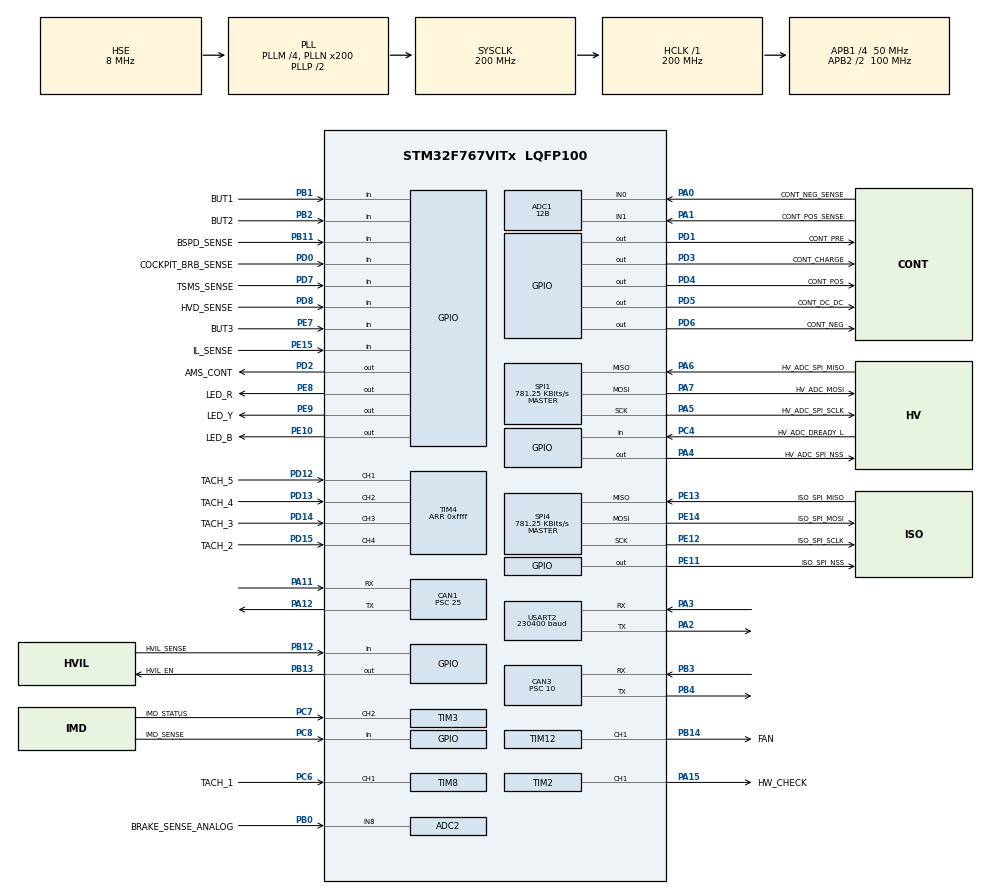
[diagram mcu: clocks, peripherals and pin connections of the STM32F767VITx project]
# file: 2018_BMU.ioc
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ADC1.Channel-0\#ChannelRegularConversion=ADC_CHANNEL_0
ADC1.ClockPrescaler=ADC_CLOCK_SYNC_PCLK_DIV4
ADC1.ContinuousConvMode=DISABLE
ADC1.DMAContinuousRequests=DISABLE
ADC1.DataAlign=ADC_DATAALIGN_RIGHT
ADC1.DiscontinuousConvMode=DISABLE
ADC1.EOCSelection=ADC_EOC_SINGLE_CONV
ADC1.EnableAnalogWatchDog=false
ADC1.ExternalTrigConv=ADC_EXTERNALTRIGCONV_T5_TRGO
ADC1.ExternalTrigConvEdge=ADC_EXTERNALTRIGCONVEDGE_RISING
ADC1.InjNumberOfConversion=0
ADC1.NbrOfConversion=1
ADC1.NbrOfConversionFlag=1
ADC1.Rank-0\#ChannelRegularConversion=1
ADC1.Resolution=ADC_RESOLUTION_12B
ADC1.SamplingTime-0\#ChannelRegularConversion=ADC_SAMPLETIME_3CYCLES
ADC1.ScanConvMode=ADC_SCAN_DISABLE
ADC1.master=1
ADC2.Channel-38\#ChannelRegularConversion=ADC_CHANNEL_8
ADC2.ClockPrescaler=ADC_CLOCK_SYNC_PCLK_DIV4
ADC2.ContinuousConvMode=DISABLE
ADC2.DMAContinuousRequests=ENABLE
ADC2.DataAlign=ADC_DATAALIGN_RIGHT
ADC2.DiscontinuousConvMode=DISABLE
ADC2.EOCSelection=ADC_EOC_SEQ_CONV
ADC2.EnableAnalogWatchDog=false
ADC2.ExternalTrigConv=ADC_EXTERNALTRIGCONV_T6_TRGO
ADC2.ExternalTrigConvEdge=ADC_EXTERNALTRIGCONVEDGE_RISING
ADC2.InjNumberOfConversion=0
ADC2.NbrOfConversion=1
ADC2.NbrOfConversionFlag=1
ADC2.Rank-38\#ChannelRegularConversion=1
ADC2.Resolution=ADC_RESOLUTION_12B
ADC2.SamplingTime-38\#ChannelRegularConversion=ADC_SAMPLETIME_28CYCLES
ADC2.ScanConvMode=ADC_SCAN_ENABLE
CAN1.BS1=CAN_BS1_6TQ
CAN1.CalculateBaudRate=250000
CAN1.CalculateTimeBit=4000
CAN1.CalculateTimeQuantum=500.0
CAN1.Prescaler=25
CAN3.ABOM=ENABLE
CAN3.AWUM=ENABLE
CAN3.BS1=CAN_BS1_8TQ
CAN3.CalculateBaudRate=500000
CAN3.CalculateTimeBit=2000
CAN3.CalculateTimeQuantum=200.0
CAN3.NART=ENABLE
CAN3.Prescaler=10
Dma.ADC2.1.Direction=DMA_PERIPH_TO_MEMORY
Dma.ADC2.1.FIFOMode=DMA_FIFOMODE_DISABLE
Dma.ADC2.1.Instance=DMA2_Stream2
Dma.ADC2.1.MemDataAlignment=DMA_MDATAALIGN_WORD
Dma.ADC2.1.MemInc=DMA_MINC_ENABLE
Dma.ADC2.1.Mode=DMA_CIRCULAR
Dma.ADC2.1.PeriphDataAlignment=DMA_PDATAALIGN_WORD
Dma.ADC2.1.PeriphInc=DMA_PINC_DISABLE
Dma.ADC2.1.Priority=DMA_PRIORITY_LOW
Dma.Request0=USART2_RX
Dma.Request1=ADC2
Dma.USART2_RX.0.Direction=DMA_PERIPH_TO_MEMORY
Dma.USART2_RX.0.FIFOMode=DMA_FIFOMODE_DISABLE
Dma.USART2_RX.0.Instance=DMA1_Stream5
Dma.USART2_RX.0.MemDataAlignment=DMA_MDATAALIGN_BYTE
Dma.USART2_RX.0.MemInc=DMA_MINC_ENABLE
Dma.USART2_RX.0.Mode=DMA_CIRCULAR
Dma.USART2_RX.0.PeriphDataAlignment=DMA_PDATAALIGN_BYTE
Dma.USART2_RX.0.PeriphInc=DMA_PINC_DISABLE
Dma.USART2_RX.0.Priority=DMA_PRIORITY_LOW
FREERTOS.INCLUDE_vTaskDelayUntil=1
FREERTOS.Tasks01=mainTask,0,1000,mainTaskFunction,As weak,NULL,Dynamic,NULL,NULL;printTaskName,-2,1000,printTask,As external,NULL,Dynamic,NULL,NULL;cliTaskName,-2,1000,cliTask,As external,NULL,Dynamic,NULL,NULL;controlTaskName,2,1000,controlTask,As external,NULL,Dynamic,NULL,NULL;PCDC,1,1000,pcdcTask,As external,NULL,Dynamic,NULL,NULL;BatteryTask,3,1000,batteryTask,As external,NULL,Dynamic,NULL,NULL;sensorTaskName,0,1000,sensorTask,As external,NULL,Dynamic,NULL,NULL;watchdogTaskNam,3,1000,watchdogTask,As external,NULL,Dynamic,NULL,NULL;HVMeasure,3,500,HVMeasureTask,As external,NULL,Dynamic,NULL,NULL;IMD,2,500,imdTask,As external,NULL,Dynamic,NULL,NULL;FaultMonitor,2,1000,faultMonitorTask,As external,NULL,Dynamic,NULL,NULL;canSendCells,0,1000,canSendCellTask,As external,NULL,Dynamic,NULL,NULL;canSendTask,3,1000,canTask,As external,NULL,Dynamic,NULL,NULL;fan,1,1000,fanTask,As external,NULL,Dynamic,NULL,NULL;stateOfCharge,0,500,socTask,Default,NULL,Dynamic,NULL,NULL
FREERTOS.configCHECK_FOR_STACK_OVERFLOW=2
FREERTOS.configGENERATE_RUN_TIME_STATS=1
FREERTOS.configTIMER_QUEUE_LENGTH=4
FREERTOS.configTIMER_TASK_PRIORITY=6
FREERTOS.configTIMER_TASK_STACK_DEPTH=1000
FREERTOS.configTOTAL_HEAP_SIZE=262144
FREERTOS.configUSE_COUNTING_SEMAPHORES=1
FREERTOS.configUSE_STATS_FORMATTING_FUNCTIONS=1
FREERTOS.configUSE_TIMERS=1
FREERTOS.configUSE_TRACE_FACILITY=1
IWDG.Reload=160
Mcu.Family=STM32F7
Mcu.Name=STM32F767VITx
Mcu.Package=LQFP100
NVIC.ADC_IRQn=true\:5\:0\:false\:false\:true\:true\:true\:true\:true
NVIC.CAN1_RX0_IRQn=true\:5\:0\:false\:false\:true\:true\:true\:true\:true
NVIC.CAN1_RX1_IRQn=true\:5\:0\:false\:false\:true\:true\:true\:true\:true
NVIC.CAN1_SCE_IRQn=true\:5\:0\:false\:false\:true\:true\:true\:true\:true
NVIC.CAN1_TX_IRQn=true\:5\:0\:false\:false\:true\:true\:true\:true\:true
NVIC.CAN3_RX0_IRQn=true\:5\:0\:false\:false\:true\:true\:true\:true\:true
NVIC.CAN3_RX1_IRQn=true\:5\:0\:false\:false\:true\:true\:true\:true\:true
NVIC.CAN3_SCE_IRQn=true\:5\:0\:false\:false\:true\:true\:true\:true\:true
NVIC.CAN3_TX_IRQn=true\:5\:0\:false\:false\:true\:true\:true\:true\:true
NVIC.DMA1_Stream5_IRQn=true\:5\:0\:false\:false\:true\:true\:false\:true\:true
NVIC.DMA2_Stream2_IRQn=true\:5\:0\:false\:false\:true\:true\:false\:true\:true
NVIC.PriorityGroup=NVIC_PRIORITYGROUP_4
NVIC.TIM3_IRQn=true\:5\:0\:false\:false\:true\:true\:true\:true\:true
NVIC.USART2_IRQn=true\:5\:0\:false\:false\:true\:true\:true\:true\:true
PA0/WKUP.GPIO_Label=CONT_NEG_SENSE
PA0/WKUP.Signal=ADCx_IN0
PA1.GPIO_Label=CONT_POS_SENSE
PA1.Signal=ADCx_IN1
PA11.Mode=CAN_Activate
PA11.Signal=CAN1_RX
PA12.Mode=CAN_Activate
PA12.Signal=CAN1_TX
PA13.Mode=Serial_Wire
PA13.Signal=SYS_JTMS-SWDIO
PA14.Mode=Serial_Wire
PA14.Signal=SYS_JTCK-SWCLK
PA15.GPIO_Label=HW_CHECK
PA15.GPIO_Speed=GPIO_SPEED_FREQ_LOW
PA15.Signal=S_TIM2_CH1_ETR
PA2.Mode=Asynchronous
PA2.Signal=USART2_TX
PA3.Mode=Asynchronous
PA3.Signal=USART2_RX
PA4.GPIO_Label=HV_ADC_SPI_NSS
PA4.GPIO_Speed=GPIO_SPEED_FREQ_VERY_HIGH
PA4.PinState=GPIO_PIN_SET
PA4.Signal=GPIO_Output
PA5.GPIO_Label=HV_ADC_SPI_SCLK
PA5.Mode=Full_Duplex_Master
PA5.Signal=SPI1_SCK
PA6.GPIO_Label=HV_ADC_SPI_MISO
PA6.Mode=Full_Duplex_Master
PA6.Signal=SPI1_MISO
PA7.GPIO_Label=HV_ADC_MOSI
PA7.Mode=Full_Duplex_Master
PA7.Signal=SPI1_MOSI
PB0.GPIO_Label=BRAKE_SENSE_ANALOG
PB0.Signal=ADCx_IN8
PB1.GPIO_Label=BUT1
PB1.Signal=GPIO_Input
PB11.GPIO_Label=BSPD_SENSE
PB11.Signal=GPIO_Input
PB12.GPIO_Label=HVIL_SENSE
PB12.GPIO_PuPd=GPIO_PULLDOWN
PB12.Signal=GPIO_Input
PB13.GPIO_Label=HVIL_EN
PB13.Signal=GPIO_Output
PB14.GPIO_Label=FAN
PB14.Signal=S_TIM12_CH1
PB2.GPIO_Label=BUT2
PB2.Signal=GPIO_Input
PB3.Mode=CAN_Activate
PB3.Signal=CAN3_RX
PB4.Mode=CAN_Activate
PB4.Signal=CAN3_TX
PC4.GPIO_Label=HV_ADC_DREADY_L
PC4.Signal=GPIO_Input
PC6.GPIO_Label=TACH_1
PC6.Signal=S_TIM8_CH1
PC7.GPIO_Label=IMD_STATUS
PC7.Signal=S_TIM3_CH2
PC8.GPIO_Label=IMD_SENSE
PC8.GPIO_PuPd=GPIO_PULLDOWN
PC8.Signal=GPIO_Input
PD0.GPIO_Label=COCKPIT_BRB_SENSE
PD0.GPIO_PuPd=GPIO_PULLDOWN
PD0.Signal=GPIO_Input
PD1.GPIO_Label=CONT_PRE
PD1.Signal=GPIO_Output
PD12.GPIO_Label=TACH_5
PD12.Signal=S_TIM4_CH1
PD13.GPIO_Label=TACH_4
PD13.Signal=S_TIM4_CH2
PD14.GPIO_Label=TACH_3
PD14.Signal=S_TIM4_CH3
PD15.GPIO_Label=TACH_2
PD15.Signal=S_TIM4_CH4
PD2.GPIO_Label=AMS_CONT
PD2.Signal=GPIO_Output
PD3.GPIO_Label=CONT_CHARGE
PD3.Signal=GPIO_Output
PD4.GPIO_Label=CONT_POS
PD4.Signal=GPIO_Output
PD5.GPIO_Label=CONT_DC_DC
PD5.Signal=GPIO_Output
PD6.GPIO_Label=CONT_NEG
PD6.Signal=GPIO_Output
PD7.GPIO_Label=TSMS_SENSE
PD7.GPIO_PuPd=GPIO_PULLDOWN
PD7.Signal=GPIO_Input
PD8.GPIO_Label=HVD_SENSE
PD8.GPIO_PuPd=GPIO_PULLDOWN
PD8.Signal=GPIO_Input
PE10.GPIO_Label=LED_B
PE10.Signal=GPIO_Output
PE11.GPIO_Label=ISO_SPI_NSS
PE11.GPIO_Speed=GPIO_SPEED_FREQ_VERY_HIGH
PE11.PinState=GPIO_PIN_SET
PE11.Signal=GPIO_Output
PE12.GPIO_Label=ISO_SPI_SCLK
PE12.Mode=Full_Duplex_Master
PE12.Signal=SPI4_SCK
PE13.GPIO_Label=ISO_SPI_MISO
PE13.Mode=Full_Duplex_Master
PE13.Signal=SPI4_MISO
PE14.GPIO_Label=ISO_SPI_MOSI
PE14.Mode=Full_Duplex_Master
PE14.Signal=SPI4_MOSI
PE15.GPIO_Label=IL_SENSE
PE15.GPIO_PuPd=GPIO_PULLDOWN
PE15.Signal=GPIO_Input
PE7.GPIO_Label=BUT3
PE7.Signal=GPIO_Input
PE8.GPIO_Label=LED_R
PE8.Signal=GPIO_Output
PE9.GPIO_Label=LED_Y
PE9.Signal=GPIO_Output
PH0/OSC_IN.Mode=HSE-External-Oscillator
PH0/OSC_IN.Signal=RCC_OSC_IN
PH1/OSC_OUT.Mode=HSE-External-Oscillator
PH1/OSC_OUT.Signal=RCC_OSC_OUT
ProjectManager.HeapSize=0x200
ProjectManager.StackSize=0x400
ProjectManager.TargetToolchain=Makefile
RCC.AHBFreq_Value=200000000
RCC.APB1CLKDivider=RCC_HCLK_DIV4
RCC.APB1Freq_Value=50000000
RCC.APB1TimFreq_Value=100000000
RCC.APB2CLKDivider=RCC_HCLK_DIV2
RCC.APB2Freq_Value=100000000
RCC.APB2TimFreq_Value=200000000
RCC.CortexFreq_Value=200000000
RCC.HCLKFreq_Value=200000000
RCC.HSE_VALUE=8000000
RCC.HSI_VALUE=16000000
RCC.LSE_VALUE=32768
RCC.PLLM=4
RCC.PLLN=200
RCC.PLLSourceVirtual=RCC_PLLSOURCE_HSE
RCC.SYSCLKFreq_VALUE=200000000
RCC.SYSCLKSource=RCC_SYSCLKSOURCE_PLLCLK
RCC.USBFreq_Value=200000000
RCC.VCOOutputFreq_Value=400000000
SH.ADCx_IN0.0=ADC1_IN0,IN0
SH.ADCx_IN1.0=ADC1_IN1,IN1
SH.ADCx_IN8.0=ADC2_IN8,IN8
SH.S_TIM12_CH1.0=TIM12_CH1,PWM Generation1 CH1
SH.S_TIM2_CH1_ETR.0=TIM2_CH1,PWM Generation1 CH1
SH.S_TIM3_CH2.0=TIM3_CH2,TriggerSource_TI2FP2
SH.S_TIM3_CH2.1=TIM3_CH2,Input_Capture2_from_TI2
SH.S_TIM3_CH2.2=TIM3_CH2,Input_Capture1_from_TI2
SH.S_TIM4_CH1.0=TIM4_CH1,Input_Capture1_from_TI1
SH.S_TIM4_CH2.0=TIM4_CH2,Input_Capture2_from_TI2
SH.S_TIM4_CH3.0=TIM4_CH3,Input_Capture3_from_TI3
SH.S_TIM4_CH4.0=TIM4_CH4,Input_Capture4_from_TI4
SH.S_TIM8_CH1.0=TIM8_CH1,Input_Capture1_from_TI1
SPI1.BaudRatePrescaler=SPI_BAUDRATEPRESCALER_128
SPI1.CLKPhase=SPI_PHASE_2EDGE
SPI1.CLKPolarity=SPI_POLARITY_HIGH
SPI1.CalculateBaudRate=781.25 KBits/s
SPI1.DataSize=SPI_DATASIZE_8BIT
SPI1.Direction=SPI_DIRECTION_2LINES
SPI1.Mode=SPI_MODE_MASTER
SPI1.VirtualType=VM_MASTER
SPI4.BaudRatePrescaler=SPI_BAUDRATEPRESCALER_128
SPI4.CLKPhase=SPI_PHASE_2EDGE
SPI4.CLKPolarity=SPI_POLARITY_HIGH
SPI4.CalculateBaudRate=781.25 KBits/s
SPI4.DataSize=SPI_DATASIZE_8BIT
SPI4.Direction=SPI_DIRECTION_2LINES
SPI4.Mode=SPI_MODE_MASTER
SPI4.VirtualType=VM_MASTER
TIM12.Channel-PWM\ Generation1\ CH1=TIM_CHANNEL_1
TIM12.Period=400
TIM12.Prescaler=9
TIM12.Pulse-PWM\ Generation1\ CH1=500
TIM2.AutoReloadPreload=TIM_AUTORELOAD_PRELOAD_DISABLE
TIM2.Channel-PWM\ Generation1\ CH1=TIM_CHANNEL_1
TIM2.Period=1000
TIM2.Prescaler=0
TIM2.Pulse-PWM\ Generation1\ CH1=500
TIM3.Channel-Input_Capture1_from_TI2=TIM_CHANNEL_1
TIM3.Channel-Input_Capture2_from_TI2=TIM_CHANNEL_2
TIM3.ICPolarity_CH1=TIM_INPUTCHANNELPOLARITY_FALLING
TIM3.Period=0xFFFF
TIM3.TIM_MasterOutputTrigger=TIM_TRGO_RESET
TIM4.Channel-Input_Capture1_from_TI1=TIM_CHANNEL_1
TIM4.Channel-Input_Capture2_from_TI2=TIM_CHANNEL_2
TIM4.Channel-Input_Capture3_from_TI3=TIM_CHANNEL_3
TIM4.Channel-Input_Capture4_from_TI4=TIM_CHANNEL_4
TIM4.Period=0xffff
TIM5.AutoReloadPreload=TIM_AUTORELOAD_PRELOAD_ENABLE
TIM5.CounterMode=TIM_COUNTERMODE_DOWN
TIM5.Period=1000
TIM5.Prescaler=16
TIM5.TIM_MasterOutputTrigger=TIM_TRGO_UPDATE
TIM6.AutoReloadPreload=TIM_AUTORELOAD_PRELOAD_ENABLE
TIM6.Period=10
TIM6.Prescaler=9999
TIM6.TIM_MasterOutputTrigger=TIM_TRGO_UPDATE
TIM8.Channel-Input_Capture1_from_TI1=TIM_CHANNEL_1
TIM9.Period=65535
TIM9.Prescaler=200
USART2.BaudRate=230400
USART2.VirtualMode-Asynchronous=VM_ASYNC
USART2.WordLength=WORDLENGTH_8B
VP_FREERTOS_VS_CMSIS_V1.Mode=CMSIS_V1
VP_IWDG_VS_IWDG.Mode=IWDG_Activate
VP_TIM2_VS_ClockSourceINT.Mode=Internal
VP_TIM3_VS_ClockSourceINT.Mode=Internal
VP_TIM3_VS_ControllerModeReset.Mode=Reset Mode
VP_TIM4_VS_ClockSourceINT.Mode=Internal
VP_TIM5_VS_ClockSourceINT.Mode=Internal
VP_TIM6_VS_ClockSourceINT.Mode=Enable_Timer
VP_TIM9_VS_ClockSourceINT.Mode=Internal
board=2018_bmu

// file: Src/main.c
/* USER CODE BEGIN Header */
/**
  ******************************************************************************
  * @file           : main.c
  * @brief          : Main program body
  ******************************************************************************
  * This notice applies to any and all portions of this file
  * that are not between comment pairs USER CODE BEGIN and
  * USER CODE END. Other portions of this file, whether
  * inserted by the user or by software development tools
  * are owned by their respective copyright owners.
  *
  * Copyright (c) 2018 STMicroelectronics International N.V.
  * All rights reserved.
  *
  * Redistribution and use in source and binary forms, with or without
  * modification, are permitted, provided that the following conditions are met:
  *
  * 1. Redistribution of source code must retain the above copyright notice,
  *    this list of conditions and the following disclaimer.
  * 2. Redistributions in binary form must reproduce the above copyright notice,
  *    this list of conditions and the following disclaimer in the documentation
  *    and/or other materials provided with the distribution.
  * 3. Neither the name of STMicroelectronics nor the names of other
  *    contributors to this software may be used to endorse or promote products
  *    derived from this software without specific written permission.
  * 4. This software, including modifications and/or derivative works of this
  *    software, must execute solely and exclusively on microcontroller or
  *    microprocessor devices manufactured by or for STMicroelectronics.
  * 5. Redistribution and use of this software other than as permitted under
  *    this license is void and will automatically terminate your rights under
  *    this license.
  *
  * THIS SOFTWARE IS PROVIDED BY STMICROELECTRONICS AND CONTRIBUTORS "AS IS"
  * AND ANY EXPRESS, IMPLIED OR STATUTORY WARRANTIES, INCLUDING, BUT NOT
  * LIMITED TO, THE IMPLIED WARRANTIES OF MERCHANTABILITY, FITNESS FOR A
  * PARTICULAR PURPOSE AND NON-INFRINGEMENT OF THIRD PARTY INTELLECTUAL PROPERTY
  * RIGHTS ARE DISCLAIMED TO THE FULLEST EXTENT PERMITTED BY LAW. IN NO EVENT
  * SHALL STMICROELECTRONICS OR CONTRIBUTORS BE LIABLE FOR ANY DIRECT, INDIRECT,
  * INCIDENTAL, SPECIAL, EXEMPLARY, OR CONSEQUENTIAL DAMAGES (INCLUDING, BUT NOT
  * LIMITED TO, PROCUREMENT OF SUBSTITUTE GOODS OR SERVICES; LOSS OF USE, DATA,
  * OR PROFITS; OR BUSINESS INTERRUPTION) HOWEVER CAUSED AND ON ANY THEORY OF
  * LIABILITY, WHETHER IN CONTRACT, STRICT LIABILITY, OR TORT (INCLUDING
  * NEGLIGENCE OR OTHERWISE) ARISING IN ANY WAY OUT OF THE USE OF THIS SOFTWARE,
  * EVEN IF ADVISED OF THE POSSIBILITY OF SUCH DAMAGE.
  *
  ******************************************************************************
  */
/* USER CODE END Header */
#include "main.h"
#include "cmsis_os.h"
#include "adc.h"
#include "can.h"
#include "dma.h"
#include "iwdg.h"
#include "spi.h"
#include "tim.h"
#include "usart.h"
#include "gpio.h"

/* USER CODE BEGIN Includes */
#include "watchdog.h"
#include "generalErrorHandler.h"
/* USER CODE END Includes */

void SystemClock_Config(void);
void MX_FREERTOS_Init(void);
/* USER CODE BEGIN PFP */
__weak void userInit() {}
/* USER CODE END PFP */

int main(void)
{
  /* USER CODE BEGIN 1 */
  checkForWDReset();
  /* USER CODE END 1 */

  /* MCU Configuration--------------------------------------------------------*/

  /* Reset of all peripherals, Initializes the Flash interface and the Systick. */
  HAL_Init();

  /* Configure the system clock */
  SystemClock_Config();

  /* Initialize all configured peripherals */
  MX_GPIO_Init();
  MX_DMA_Init();
  MX_ADC1_Init();
  MX_ADC2_Init();
  MX_CAN3_Init();
  MX_SPI1_Init();
  MX_SPI4_Init();
  MX_TIM3_Init();
  MX_TIM5_Init();
  MX_USART2_UART_Init();
  MX_TIM4_Init();
  MX_IWDG_Init();
  MX_TIM6_Init();
  MX_TIM9_Init();
  MX_CAN1_Init();
  MX_TIM8_Init();
  MX_TIM12_Init();
  MX_TIM2_Init();
  /* USER CODE BEGIN 2 */
  userInit();
  printWDResetState();
  handleWatchdogReset();
  /* USER CODE END 2 */

  /* Call init function for freertos objects (in freertos.c) */
  MX_FREERTOS_Init();
  /* Start scheduler */
  osKernelStart();

  /* We should never get here as control is now taken by the scheduler */
  /* Infinite loop */
  while (1)
  {

  }
}

void SystemClock_Config(void)
{
  RCC_OscInitTypeDef RCC_OscInitStruct = {0};
  RCC_ClkInitTypeDef RCC_ClkInitStruct = {0};
  RCC_PeriphCLKInitTypeDef PeriphClkInitStruct = {0};

  /** Configure the main internal regulator output voltage
  */
  __HAL_RCC_PWR_CLK_ENABLE();
  __HAL_PWR_VOLTAGESCALING_CONFIG(PWR_REGULATOR_VOLTAGE_SCALE1);
  /** Initializes the RCC Oscillators according to the specified parameters
  * in the RCC_OscInitTypeDef structure.
  */
  RCC_OscInitStruct.OscillatorType = RCC_OSCILLATORTYPE_LSI|RCC_OSCILLATORTYPE_HSE;
  RCC_OscInitStruct.HSEState = RCC_HSE_ON;
  RCC_OscInitStruct.LSIState = RCC_LSI_ON;
  RCC_OscInitStruct.PLL.PLLState = RCC_PLL_ON;
  RCC_OscInitStruct.PLL.PLLSource = RCC_PLLSOURCE_HSE;
  RCC_OscInitStruct.PLL.PLLM = 4;
  RCC_OscInitStruct.PLL.PLLN = 200;
  RCC_OscInitStruct.PLL.PLLP = RCC_PLLP_DIV2;
  RCC_OscInitStruct.PLL.PLLQ = 2;
  RCC_OscInitStruct.PLL.PLLR = 2;
  if (HAL_RCC_OscConfig(&RCC_OscInitStruct) != HAL_OK)
  {
    Error_Handler();
  }
  /** Activate the Over-Drive mode
  */
  if (HAL_PWREx_EnableOverDrive() != HAL_OK)
  {
    Error_Handler();
  }
  /** Initializes the CPU, AHB and APB buses clocks
  */
  RCC_ClkInitStruct.ClockType = RCC_CLOCKTYPE_HCLK|RCC_CLOCKTYPE_SYSCLK
                              |RCC_CLOCKTYPE_PCLK1|RCC_CLOCKTYPE_PCLK2;
  RCC_ClkInitStruct.SYSCLKSource = RCC_SYSCLKSOURCE_PLLCLK;
  RCC_ClkInitStruct.AHBCLKDivider = RCC_SYSCLK_DIV1;
  RCC_ClkInitStruct.APB1CLKDivider = RCC_HCLK_DIV4;
  RCC_ClkInitStruct.APB2CLKDivider = RCC_HCLK_DIV2;

  if (HAL_RCC_ClockConfig(&RCC_ClkInitStruct, FLASH_LATENCY_6) != HAL_OK)
  {
    Error_Handler();
  }
  PeriphClkInitStruct.PeriphClockSelection = RCC_PERIPHCLK_USART2;
  PeriphClkInitStruct.Usart2ClockSelection = RCC_USART2CLKSOURCE_PCLK1;
  if (HAL_RCCEx_PeriphCLKConfig(&PeriphClkInitStruct) != HAL_OK)
  {
    Error_Handler();
  }
}

void Error_Handler(void)
{
  __disable_irq();
  while (1)
  {
  }
}

/************************ (C) COPYRIGHT STMicroelectronics *****END OF FILE****/

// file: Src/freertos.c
/* USER CODE BEGIN Header */
/**
  ******************************************************************************
  * File Name          : freertos.c
  * Description        : Code for freertos applications
  ******************************************************************************
  * This notice applies to any and all portions of this file
  * that are not between comment pairs USER CODE BEGIN and
  * USER CODE END. Other portions of this file, whether
  * inserted by the user or by software development tools
  * are owned by their respective copyright owners.
  *
  * Copyright (c) 2018 STMicroelectronics International N.V.
  * All rights reserved.
  *
  * Redistribution and use in source and binary forms, with or without
  * modification, are permitted, provided that the following conditions are met:
  *
  * 1. Redistribution of source code must retain the above copyright notice,
  *    this list of conditions and the following disclaimer.
  * 2. Redistributions in binary form must reproduce the above copyright notice,
  *    this list of conditions and the following disclaimer in the documentation
  *    and/or other materials provided with the distribution.
  * 3. Neither the name of STMicroelectronics nor the names of other
  *    contributors to this software may be used to endorse or promote products
  *    derived from this software without specific written permission.
  * 4. This software, including modifications and/or derivative works of this
  *    software, must execute solely and exclusively on microcontroller or
  *    microprocessor devices manufactured by or for STMicroelectronics.
  * 5. Redistribution and use of this software other than as permitted under
  *    this license is void and will automatically terminate your rights under
  *    this license.
  *
  * THIS SOFTWARE IS PROVIDED BY STMICROELECTRONICS AND CONTRIBUTORS "AS IS"
  * AND ANY EXPRESS, IMPLIED OR STATUTORY WARRANTIES, INCLUDING, BUT NOT
  * LIMITED TO, THE IMPLIED WARRANTIES OF MERCHANTABILITY, FITNESS FOR A
  * PARTICULAR PURPOSE AND NON-INFRINGEMENT OF THIRD PARTY INTELLECTUAL PROPERTY
  * RIGHTS ARE DISCLAIMED TO THE FULLEST EXTENT PERMITTED BY LAW. IN NO EVENT
  * SHALL STMICROELECTRONICS OR CONTRIBUTORS BE LIABLE FOR ANY DIRECT, INDIRECT,
  * INCIDENTAL, SPECIAL, EXEMPLARY, OR CONSEQUENTIAL DAMAGES (INCLUDING, BUT NOT
  * LIMITED TO, PROCUREMENT OF SUBSTITUTE GOODS OR SERVICES; LOSS OF USE, DATA,
  * OR PROFITS; OR BUSINESS INTERRUPTION) HOWEVER CAUSED AND ON ANY THEORY OF
  * LIABILITY, WHETHER IN CONTRACT, STRICT LIABILITY, OR TORT (INCLUDING
  * NEGLIGENCE OR OTHERWISE) ARISING IN ANY WAY OUT OF THE USE OF THIS SOFTWARE,
  * EVEN IF ADVISED OF THE POSSIBILITY OF SUCH DAMAGE.
  *
  ******************************************************************************
  */
/* USER CODE END Header */

#include "FreeRTOS.h"
#include "task.h"
#include "main.h"
#include "cmsis_os.h"

osThreadId mainTaskHandle;
osThreadId printTaskNameHandle;
osThreadId cliTaskNameHandle;
osThreadId controlTaskNameHandle;
osThreadId PCDCHandle;
osThreadId BatteryTaskHandle;
osThreadId sensorTaskNameHandle;
osThreadId watchdogTaskNamHandle;
osThreadId HVMeasureHandle;
osThreadId IMDHandle;
osThreadId FaultMonitorHandle;
osThreadId canSendCellsHandle;
osThreadId canSendTaskHandle;
osThreadId fanHandle;
osThreadId stateOfChargeHandle;
osThreadId wirelessCANHandle;

void mainTaskFunction(void const * argument);
extern void printTask(void const * argument);
extern void cliTask(void const * argument);
extern void controlTask(void const * argument);
extern void pcdcTask(void const * argument);
extern void batteryTask(void const * argument);
extern void sensorTask(void const * argument);
extern void watchdogTask(void const * argument);
extern void HVMeasureTask(void const * argument);
extern void imdTask(void const * argument);
extern void faultMonitorTask(void const * argument);
extern void canSendCellTask(void const * argument);
extern void canTask(void const * argument);
extern void fanTask(void const * argument);
void socTask(void const * argument);
extern void wirelessCANTask(void const * argument);

void MX_FREERTOS_Init(void); /* (MISRA C 2004 rule 8.1) */

/* GetIdleTaskMemory prototype (linked to static allocation support) */
void vApplicationGetIdleTaskMemory( StaticTask_t **ppxIdleTaskTCBBuffer, StackType_t **ppxIdleTaskStackBuffer, uint32_t *pulIdleTaskStackSize );

/* GetTimerTaskMemory prototype (linked to static allocation support) */
void vApplicationGetTimerTaskMemory( StaticTask_t **ppxTimerTaskTCBBuffer, StackType_t **ppxTimerTaskStackBuffer, uint32_t *pulTimerTaskStackSize );

/* Hook prototypes */
void configureTimerForRunTimeStats(void);
unsigned long getRunTimeCounterValue(void);
void vApplicationStackOverflowHook(xTaskHandle xTask, signed char *pcTaskName);

/* USER CODE BEGIN 1 */
/* Functions needed when configGENERATE_RUN_TIME_STATS is on */
__weak void configureTimerForRunTimeStats(void)
{

}

__weak unsigned long getRunTimeCounterValue(void)
{
return 0;
}
/* USER CODE END 1 */

/* USER CODE BEGIN 4 */
__weak void vApplicationStackOverflowHook(xTaskHandle xTask, signed char *pcTaskName)
{
   /* Run time stack overflow checking is performed if
   configCHECK_FOR_STACK_OVERFLOW is defined to 1 or 2. This hook function is
   called if a stack overflow is detected. */
}
/* USER CODE END 4 */

/* USER CODE BEGIN GET_IDLE_TASK_MEMORY */
static StaticTask_t xIdleTaskTCBBuffer;
static StackType_t xIdleStack[configMINIMAL_STACK_SIZE];

void vApplicationGetIdleTaskMemory( StaticTask_t **ppxIdleTaskTCBBuffer, StackType_t **ppxIdleTaskStackBuffer, uint32_t *pulIdleTaskStackSize )
{
  *ppxIdleTaskTCBBuffer = &xIdleTaskTCBBuffer;
  *ppxIdleTaskStackBuffer = &xIdleStack[0];
  *pulIdleTaskStackSize = configMINIMAL_STACK_SIZE;
  /* place for user code */
}
/* USER CODE END GET_IDLE_TASK_MEMORY */

/* USER CODE BEGIN GET_TIMER_TASK_MEMORY */
static StaticTask_t xTimerTaskTCBBuffer;
static StackType_t xTimerStack[configTIMER_TASK_STACK_DEPTH];

void vApplicationGetTimerTaskMemory( StaticTask_t **ppxTimerTaskTCBBuffer, StackType_t **ppxTimerTaskStackBuffer, uint32_t *pulTimerTaskStackSize )
{
  *ppxTimerTaskTCBBuffer = &xTimerTaskTCBBuffer;
  *ppxTimerTaskStackBuffer = &xTimerStack[0];
  *pulTimerTaskStackSize = configTIMER_TASK_STACK_DEPTH;
  /* place for user code */
}
/* USER CODE END GET_TIMER_TASK_MEMORY */

void MX_FREERTOS_Init(void) {

  /* Create the thread(s) */
  /* definition and creation of mainTask */
  osThreadDef(mainTask, mainTaskFunction, osPriorityNormal, 0, 1000);
  mainTaskHandle = osThreadCreate(osThread(mainTask), NULL);

  /* definition and creation of printTaskName */
  osThreadDef(printTaskName, printTask, osPriorityLow, 0, 1000);
  printTaskNameHandle = osThreadCreate(osThread(printTaskName), NULL);

  /* definition and creation of cliTaskName */
  osThreadDef(cliTaskName, cliTask, osPriorityLow, 0, 1000);
  cliTaskNameHandle = osThreadCreate(osThread(cliTaskName), NULL);

  /* definition and creation of controlTaskName */
  osThreadDef(controlTaskName, controlTask, osPriorityHigh, 0, 1000);
  controlTaskNameHandle = osThreadCreate(osThread(controlTaskName), NULL);

  /* definition and creation of PCDC */
  osThreadDef(PCDC, pcdcTask, osPriorityAboveNormal, 0, 1000);
  PCDCHandle = osThreadCreate(osThread(PCDC), NULL);

  /* definition and creation of BatteryTask */
  osThreadDef(BatteryTask, batteryTask, osPriorityRealtime, 0, 1000);
  BatteryTaskHandle = osThreadCreate(osThread(BatteryTask), NULL);

  /* definition and creation of sensorTaskName */
  osThreadDef(sensorTaskName, sensorTask, osPriorityNormal, 0, 1000);
  sensorTaskNameHandle = osThreadCreate(osThread(sensorTaskName), NULL);

  /* definition and creation of watchdogTaskNam */
  osThreadDef(watchdogTaskNam, watchdogTask, osPriorityRealtime, 0, 1000);
  watchdogTaskNamHandle = osThreadCreate(osThread(watchdogTaskNam), NULL);

  /* definition and creation of HVMeasure */
  osThreadDef(HVMeasure, HVMeasureTask, osPriorityRealtime, 0, 500);
  HVMeasureHandle = osThreadCreate(osThread(HVMeasure), NULL);

  /* definition and creation of IMD */
  osThreadDef(IMD, imdTask, osPriorityHigh, 0, 500);
  IMDHandle = osThreadCreate(osThread(IMD), NULL);

  /* definition and creation of FaultMonitor */
  osThreadDef(FaultMonitor, faultMonitorTask, osPriorityHigh, 0, 1000);
  FaultMonitorHandle = osThreadCreate(osThread(FaultMonitor), NULL);

  /* definition and creation of canSendCells */
  osThreadDef(canSendCells, canSendCellTask, osPriorityNormal, 0, 1000);
  canSendCellsHandle = osThreadCreate(osThread(canSendCells), NULL);

  /* definition and creation of canSendTask */
  osThreadDef(canSendTask, canTask, osPriorityRealtime, 0, 1000);
  canSendTaskHandle = osThreadCreate(osThread(canSendTask), NULL);

  /* definition and creation of fan */
  osThreadDef(fan, fanTask, osPriorityAboveNormal, 0, 1000);
  fanHandle = osThreadCreate(osThread(fan), NULL);

  /* definition and creation of stateOfCharge */
  osThreadDef(stateOfCharge, socTask, osPriorityNormal, 0, 500);
  stateOfChargeHandle = osThreadCreate(osThread(stateOfCharge), NULL);

  /* definition and creation of wirelessCAN */
  osThreadDef(wirelessCAN, wirelessCANTask, osPriorityNormal, 0, 128);
  wirelessCANHandle = osThreadCreate(osThread(wirelessCAN), NULL);

}

__weak void mainTaskFunction(void const * argument)
{
  for(;;)
  {
    osDelay(1);
  }
}

void socTask(void const * argument)
{
  for(;;)
  {
    osDelay(1);
  }
}

/************************ (C) COPYRIGHT STMicroelectronics *****END OF FILE****/
